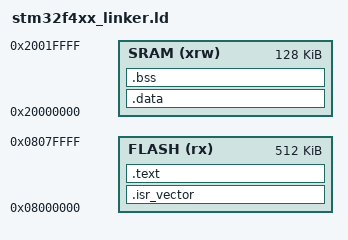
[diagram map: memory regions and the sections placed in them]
ENTRY(Reset_Handler)

_estack = ORIGIN(SRAM) + LENGTH(SRAM);

MEMORY
{
    FLASH (rx) : ORIGIN = 0x08000000, LENGTH = 512K
    SRAM (xrw) : ORIGIN = 0x20000000, LENGTH = 128K
}

SECTIONS
{
    .isr_vector :
    {
        . = ALIGN(4);
        KEEP(*(.isr_vector))
        . = ALIGN(4);
    } > FLASH

    .text :
    {
        . = ALIGN(4);
        *(.text)
        *(.text*)
        *(.rodata)
        *(.rodata*)
        . = ALIGN(4);
        _etext = .;
    } >FLASH

    .data : AT ( _etext )
    {
        . = ALIGN(4);
        _sdata = .;
        *(.data)
        *(.data*)
        . = ALIGN(4);
        _edata = .;
    } >SRAM

    .bss :
    {
        . = ALIGN(4);
        _sbss = .;
        *(.bss)
        *(.bss*)
        *(COMMON)
        . = ALIGN(4);
        _ebss = .;
    } >SRAM

    /DISCARD/ : { *(.eh_frame) *(.ARM.exidx) *(.ARM.extab)}
} 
